VERSION "PDbcCodec 2.0.5"

NS_ :

BS_:

BU_: CanMatrix CanMatrixMZ1_Can CanMatrixMB1_Can CanMatrixMZ1_i40OSupplyActual CanMatrixMB1_i40OSupplyActual CanMatrixDigitemp_temp CanMatrixTUMG_IOLink

BO_ 385 Message_181: 7 CanMatrixMZ1_Can
 SG_ MZ1_Can_1_deg : 0|16@1+ (0.005493,0) [0|360] "°" Vector__XXX
 SG_ MZ1_Can_1_turn : 16|8@1+ (1,0) [0|3000] "turn" Vector__XXX

BO_ 386 Message_182: 7 CanMatrixMZ1_Can
 SG_ MZ1_Can_2_deg : 0|16@1+ (0.005493,0) [0|360] "°" Vector__XXX
 SG_ MZ1_Can_2_turn : 16|8@1+ (1,0) [0|3000] "turn" Vector__XXX

BO_ 387 Message_183: 7 CanMatrixMZ1_Can
 SG_ MZ1_Can_3_deg : 0|16@1+ (0.005493,0) [0|360] "°" Vector__XXX
 SG_ MZ1_Can_3_turn : 16|8@1+ (1,0) [0|3000] "turn" Vector__XXX

BO_ 388 Message_184: 7 CanMatrixMZ1_Can
 SG_ MZ1_Can_4_deg : 0|16@1+ (0.005493,0) [0|360] "°" Vector__XXX
 SG_ MZ1_Can_4_turn : 16|8@1+ (1,0) [0|3000] "turn" Vector__XXX

BO_ 389 Message_185: 7 CanMatrixMZ1_Can
 SG_ MZ1_Can_5_deg : 0|16@1+ (0.005493,0) [0|360] "°" Vector__XXX
 SG_ MZ1_Can_5_turn : 16|8@1+ (1,0) [0|3000] "turn" Vector__XXX

BO_ 390 Message_186: 7 CanMatrixMZ1_Can
 SG_ MZ1_Can_6_deg : 0|16@1+ (0.005493,0) [0|360] "°" Vector__XXX
 SG_ MZ1_Can_6_turn : 16|8@1+ (1,0) [0|3000] "turn" Vector__XXX

BO_ 391 Message_187: 7 CanMatrixMZ1_Can
 SG_ MZ1_Can_7_deg : 0|16@1+ (0.005493,0) [0|360] "°" Vector__XXX
 SG_ MZ1_Can_7_turn : 16|8@1+ (1,0) [0|3000] "turn" Vector__XXX

BO_ 392 Message_188: 7 CanMatrixMZ1_Can
 SG_ MZ1_Can_8_deg : 0|16@1+ (0.005493,0) [0|360] "°" Vector__XXX
 SG_ MZ1_Can_8_turn : 16|8@1+ (1,0) [0|3000] "turn" Vector__XXX

BO_ 393 Message_189: 7 CanMatrixMZ1_Can
 SG_ MZ1_Can_9_deg : 0|16@1+ (0.005493,0) [0|360] "°" Vector__XXX
 SG_ MZ1_Can_9_turn : 16|8@1+ (1,0) [0|3000] "turn" Vector__XXX

BO_ 394 Message_18A: 7 CanMatrixMZ1_Can
 SG_ MZ1_Can_10_deg : 0|16@1+ (0.005493,0) [0|360] "°" Vector__XXX
 SG_ MZ1_Can_10_turn : 16|8@1+ (1,0) [0|3000] "turn" Vector__XXX

BO_ 395 Message_18B: 7 CanMatrixMB1_Can
 SG_ MB1_Can_1_deg : 0|16@1+ (0.005493,0) [0|360] "°" Vector__XXX
 SG_ MB1_Can_1_turn : 16|8@1+ (1,0) [0|3000] "turn" Vector__XXX

BO_ 396 Message_18C: 7 CanMatrixMB1_Can
 SG_ MB1_Can_2_deg : 0|16@1+ (0.005493,0) [0|360] "°" Vector__XXX
 SG_ MB1_Can_2_turn : 16|8@1+ (1,0) [0|3000] "turn" Vector__XXX

BO_ 397 Message_18D: 7 CanMatrixMB1_Can
 SG_ MB1_Can_3_deg : 0|16@1+ (0.005493,0) [0|360] "°" Vector__XXX
 SG_ MB1_Can_3_turn : 16|8@1+ (1,0) [0|3000] "turn" Vector__XXX

BO_ 398 Message_18E: 7 CanMatrixMB1_Can
 SG_ MB1_Can_4_deg : 0|16@1+ (0.005493,0) [0|360] "°" Vector__XXX
 SG_ MB1_Can_4_turn : 16|8@1+ (1,0) [0|3000] "turn" Vector__XXX

BO_ 399 Message_18F: 7 CanMatrixMB1_Can
 SG_ MB1_Can_5_deg : 0|16@1+ (0.005493,0) [0|360] "°" Vector__XXX
 SG_ MB1_Can_5_turn : 16|8@1+ (1,0) [0|3000] "turn" Vector__XXX

BO_ 400 Message_190: 7 CanMatrixMB1_Can
 SG_ MB1_Can_6_deg : 0|16@1+ (0.005493,0) [0|360] "°" Vector__XXX
 SG_ MB1_Can_6_turn : 16|8@1+ (1,0) [0|3000] "turn" Vector__XXX

BO_ 401 Message_191: 7 CanMatrixMB1_Can
 SG_ MB1_Can_7_deg : 0|16@1+ (0.005493,0) [0|360] "°" Vector__XXX
 SG_ MB1_Can_7_turn : 16|8@1+ (1,0) [0|3000] "turn" Vector__XXX

BO_ 402 Message_192: 7 CanMatrixMB1_Can
 SG_ MB1_Can_8_deg : 0|16@1+ (0.005493,0) [0|360] "°" Vector__XXX
 SG_ MB1_Can_8_turn : 16|8@1+ (1,0) [0|3000] "turn" Vector__XXX

BO_ 403 Message_193: 7 CanMatrixMB1_Can
 SG_ MB1_Can_9_deg : 0|16@1+ (0.005493,0) [0|360] "°" Vector__XXX
 SG_ MB1_Can_9_turn : 16|8@1+ (1,0) [0|3000] "turn" Vector__XXX

BO_ 404 Message_194: 7 CanMatrixMB1_Can
 SG_ MB1_Can_10_deg : 0|16@1+ (0.005493,0) [0|360] "°" Vector__XXX
 SG_ MB1_Can_10_turn : 16|8@1+ (1,0) [0|3000] "turn" Vector__XXX

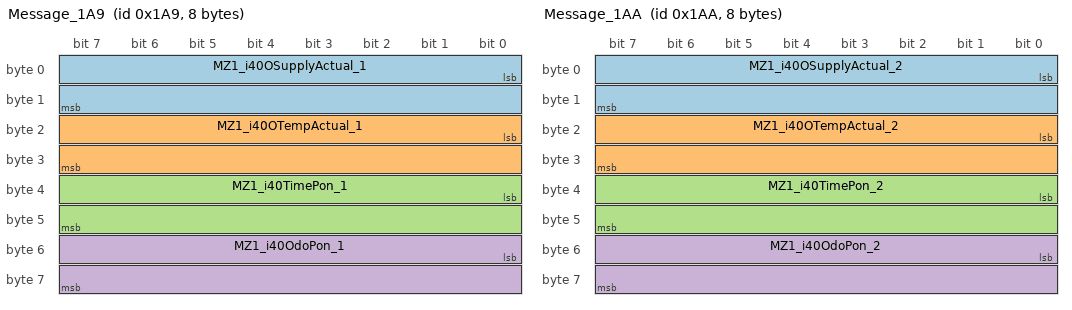
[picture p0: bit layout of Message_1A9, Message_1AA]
BO_ 425 Message_1A9: 8 CanMatrixMZ1_i40OSupplyActual
 SG_ MZ1_i40OSupplyActual_1 : 0|16@1+ (0.1,0) [0|3000] "V" Vector__XXX
 SG_ MZ1_i40OTempActual_1 : 16|16@1+ (0.1,-50) [0|3000] "°C" Vector__XXX
 SG_ MZ1_i40TimePon_1 : 32|16@1+ (1,0) [0|3000] "h" Vector__XXX
 SG_ MZ1_i40OdoPon_1 : 48|16@1+ (1,0) [0|3000] "h" Vector__XXX

BO_ 426 Message_1AA: 8 CanMatrixMZ1_i40OSupplyActual
 SG_ MZ1_i40OSupplyActual_2 : 0|16@1+ (0.1,0) [0|3000] "V" Vector__XXX
 SG_ MZ1_i40OTempActual_2 : 16|16@1+ (0.1,-50) [0|3000] "°C" Vector__XXX
 SG_ MZ1_i40TimePon_2 : 32|16@1+ (1,0) [0|3000] "h" Vector__XXX
 SG_ MZ1_i40OdoPon_2 : 48|16@1+ (1,0) [0|3000] "h" Vector__XXX

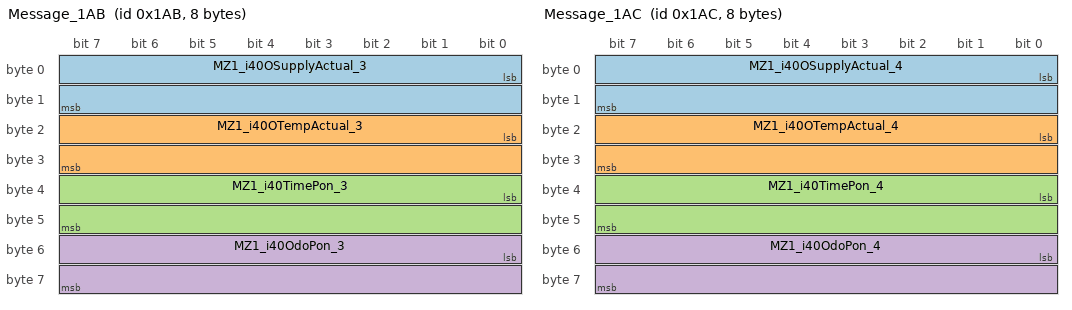
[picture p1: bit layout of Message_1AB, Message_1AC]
BO_ 427 Message_1AB: 8 CanMatrixMZ1_i40OSupplyActual
 SG_ MZ1_i40OSupplyActual_3 : 0|16@1+ (0.1,0) [0|3000] "V" Vector__XXX
 SG_ MZ1_i40OTempActual_3 : 16|16@1+ (0.1,-50) [0|3000] "°C" Vector__XXX
 SG_ MZ1_i40TimePon_3 : 32|16@1+ (1,0) [0|3000] "h" Vector__XXX
 SG_ MZ1_i40OdoPon_3 : 48|16@1+ (1,0) [0|3000] "h" Vector__XXX

BO_ 428 Message_1AC: 8 CanMatrixMZ1_i40OSupplyActual
 SG_ MZ1_i40OSupplyActual_4 : 0|16@1+ (0.1,0) [0|3000] "V" Vector__XXX
 SG_ MZ1_i40OTempActual_4 : 16|16@1+ (0.1,-50) [0|3000] "°C" Vector__XXX
 SG_ MZ1_i40TimePon_4 : 32|16@1+ (1,0) [0|3000] "h" Vector__XXX
 SG_ MZ1_i40OdoPon_4 : 48|16@1+ (1,0) [0|3000] "h" Vector__XXX

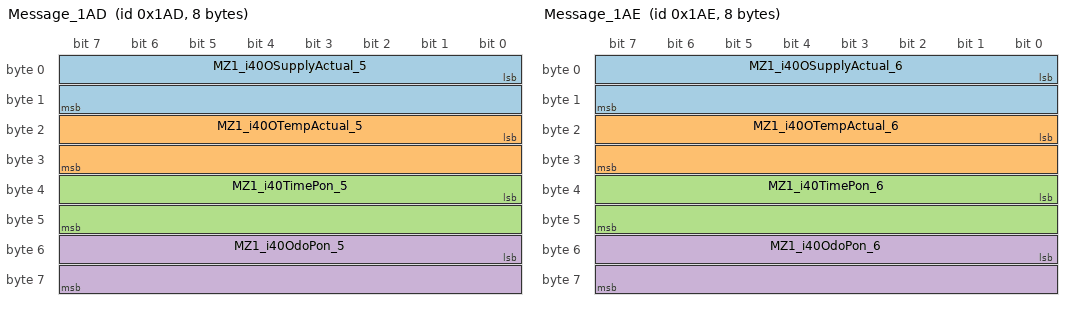
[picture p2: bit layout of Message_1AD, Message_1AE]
BO_ 429 Message_1AD: 8 CanMatrixMZ1_i40OSupplyActual
 SG_ MZ1_i40OSupplyActual_5 : 0|16@1+ (0.1,0) [0|3000] "V" Vector__XXX
 SG_ MZ1_i40OTempActual_5 : 16|16@1+ (0.1,-50) [0|3000] "°C" Vector__XXX
 SG_ MZ1_i40TimePon_5 : 32|16@1+ (1,0) [0|3000] "h" Vector__XXX
 SG_ MZ1_i40OdoPon_5 : 48|16@1+ (1,0) [0|3000] "h" Vector__XXX

BO_ 430 Message_1AE: 8 CanMatrixMZ1_i40OSupplyActual
 SG_ MZ1_i40OSupplyActual_6 : 0|16@1+ (0.1,0) [0|3000] "V" Vector__XXX
 SG_ MZ1_i40OTempActual_6 : 16|16@1+ (0.1,-50) [0|3000] "°C" Vector__XXX
 SG_ MZ1_i40TimePon_6 : 32|16@1+ (1,0) [0|3000] "h" Vector__XXX
 SG_ MZ1_i40OdoPon_6 : 48|16@1+ (1,0) [0|3000] "h" Vector__XXX

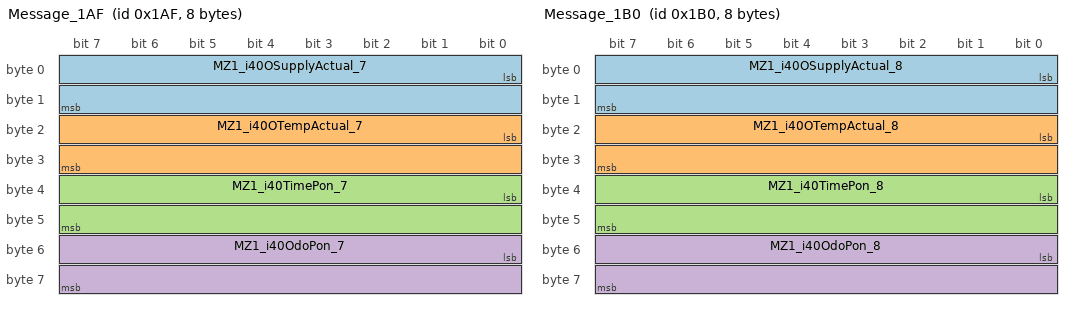
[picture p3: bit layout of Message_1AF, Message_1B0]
BO_ 431 Message_1AF: 8 CanMatrixMZ1_i40OSupplyActual
 SG_ MZ1_i40OSupplyActual_7 : 0|16@1+ (0.1,0) [0|3000] "V" Vector__XXX
 SG_ MZ1_i40OTempActual_7 : 16|16@1+ (0.1,-50) [0|3000] "°C" Vector__XXX
 SG_ MZ1_i40TimePon_7 : 32|16@1+ (1,0) [0|3000] "h" Vector__XXX
 SG_ MZ1_i40OdoPon_7 : 48|16@1+ (1,0) [0|3000] "h" Vector__XXX

BO_ 432 Message_1B0: 8 CanMatrixMZ1_i40OSupplyActual
 SG_ MZ1_i40OSupplyActual_8 : 0|16@1+ (0.1,0) [0|3000] "V" Vector__XXX
 SG_ MZ1_i40OTempActual_8 : 16|16@1+ (0.1,-50) [0|3000] "°C" Vector__XXX
 SG_ MZ1_i40TimePon_8 : 32|16@1+ (1,0) [0|3000] "h" Vector__XXX
 SG_ MZ1_i40OdoPon_8 : 48|16@1+ (1,0) [0|3000] "h" Vector__XXX

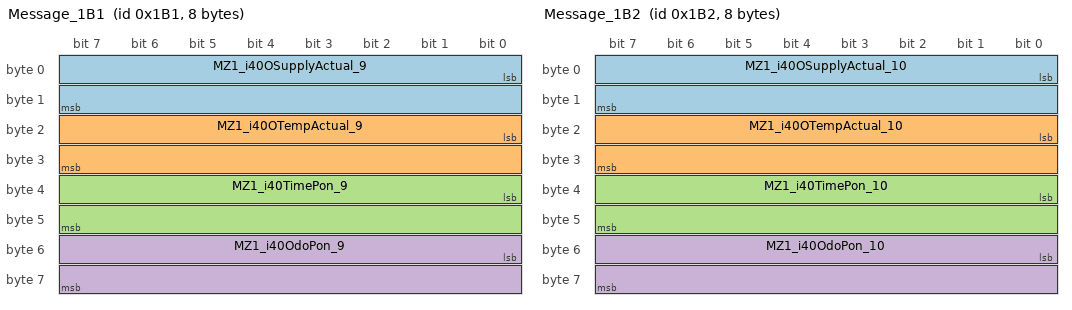
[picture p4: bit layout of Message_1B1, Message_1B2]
BO_ 433 Message_1B1: 8 CanMatrixMZ1_i40OSupplyActual
 SG_ MZ1_i40OSupplyActual_9 : 0|16@1+ (0.1,0) [0|3000] "V" Vector__XXX
 SG_ MZ1_i40OTempActual_9 : 16|16@1+ (0.1,-50) [0|3000] "°C" Vector__XXX
 SG_ MZ1_i40TimePon_9 : 32|16@1+ (1,0) [0|3000] "h" Vector__XXX
 SG_ MZ1_i40OdoPon_9 : 48|16@1+ (1,0) [0|3000] "h" Vector__XXX

BO_ 434 Message_1B2: 8 CanMatrixMZ1_i40OSupplyActual
 SG_ MZ1_i40OSupplyActual_10 : 0|16@1+ (0.1,0) [0|3000] "V" Vector__XXX
 SG_ MZ1_i40OTempActual_10 : 16|16@1+ (0.1,-50) [0|3000] "°C" Vector__XXX
 SG_ MZ1_i40TimePon_10 : 32|16@1+ (1,0) [0|3000] "h" Vector__XXX
 SG_ MZ1_i40OdoPon_10 : 48|16@1+ (1,0) [0|3000] "h" Vector__XXX

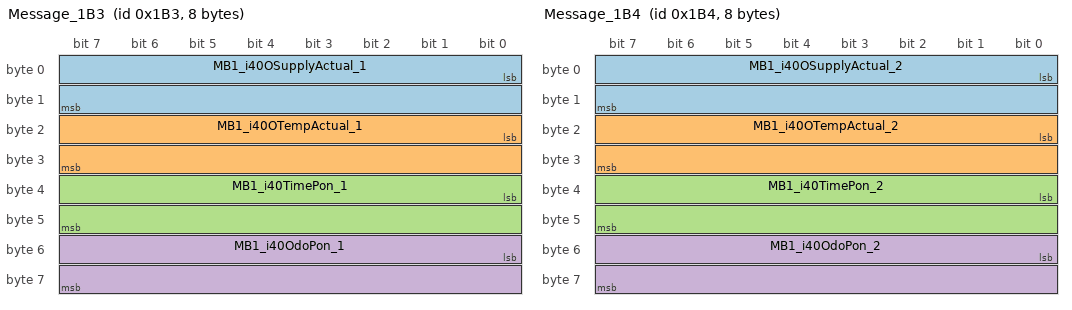
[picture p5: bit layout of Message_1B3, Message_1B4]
BO_ 435 Message_1B3: 8 CanMatrixMB1_i40OSupplyActual
 SG_ MB1_i40OSupplyActual_1 : 0|16@1+ (0.1,0) [0|3000] "V" Vector__XXX
 SG_ MB1_i40OTempActual_1 : 16|16@1+ (0.1,0) [0|3000] "°C" Vector__XXX
 SG_ MB1_i40TimePon_1 : 32|16@1+ (1,0) [0|3000] "h" Vector__XXX
 SG_ MB1_i40OdoPon_1 : 48|16@1+ (1,0) [0|3000] "h" Vector__XXX

BO_ 436 Message_1B4: 8 CanMatrixMB1_i40OSupplyActual
 SG_ MB1_i40OSupplyActual_2 : 0|16@1+ (0.1,0) [0|3000] "V" Vector__XXX
 SG_ MB1_i40OTempActual_2 : 16|16@1+ (0.1,0) [0|3000] "°C" Vector__XXX
 SG_ MB1_i40TimePon_2 : 32|16@1+ (1,0) [0|3000] "h" Vector__XXX
 SG_ MB1_i40OdoPon_2 : 48|16@1+ (1,0) [0|3000] "h" Vector__XXX

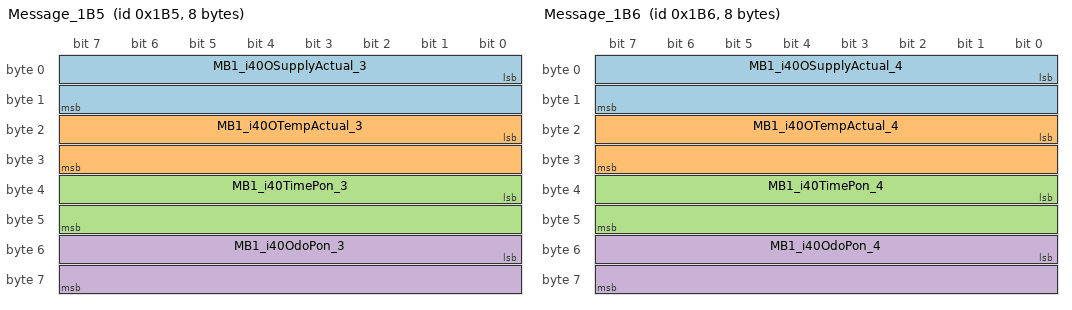
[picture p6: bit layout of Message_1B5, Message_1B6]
BO_ 437 Message_1B5: 8 CanMatrixMB1_i40OSupplyActual
 SG_ MB1_i40OSupplyActual_3 : 0|16@1+ (0.1,0) [0|3000] "V" Vector__XXX
 SG_ MB1_i40OTempActual_3 : 16|16@1+ (0.1,0) [0|3000] "°C" Vector__XXX
 SG_ MB1_i40TimePon_3 : 32|16@1+ (1,0) [0|3000] "h" Vector__XXX
 SG_ MB1_i40OdoPon_3 : 48|16@1+ (1,0) [0|3000] "h" Vector__XXX

BO_ 438 Message_1B6: 8 CanMatrixMB1_i40OSupplyActual
 SG_ MB1_i40OSupplyActual_4 : 0|16@1+ (0.1,0) [0|3000] "V" Vector__XXX
 SG_ MB1_i40OTempActual_4 : 16|16@1+ (0.1,0) [0|3000] "°C" Vector__XXX
 SG_ MB1_i40TimePon_4 : 32|16@1+ (1,0) [0|3000] "h" Vector__XXX
 SG_ MB1_i40OdoPon_4 : 48|16@1+ (1,0) [0|3000] "h" Vector__XXX

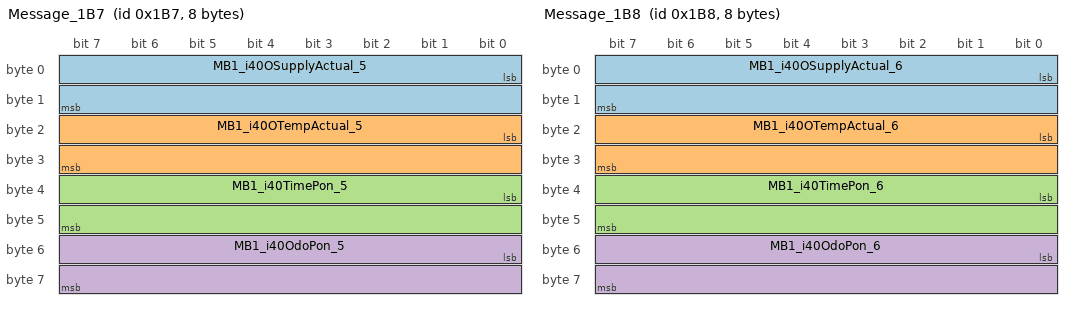
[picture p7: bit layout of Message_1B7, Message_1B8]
BO_ 439 Message_1B7: 8 CanMatrixMB1_i40OSupplyActual
 SG_ MB1_i40OSupplyActual_5 : 0|16@1+ (0.1,0) [0|3000] "V" Vector__XXX
 SG_ MB1_i40OTempActual_5 : 16|16@1+ (0.1,0) [0|3000] "°C" Vector__XXX
 SG_ MB1_i40TimePon_5 : 32|16@1+ (1,0) [0|3000] "h" Vector__XXX
 SG_ MB1_i40OdoPon_5 : 48|16@1+ (1,0) [0|3000] "h" Vector__XXX

BO_ 440 Message_1B8: 8 CanMatrixMB1_i40OSupplyActual
 SG_ MB1_i40OSupplyActual_6 : 0|16@1+ (0.1,0) [0|3000] "V" Vector__XXX
 SG_ MB1_i40OTempActual_6 : 16|16@1+ (0.1,0) [0|3000] "°C" Vector__XXX
 SG_ MB1_i40TimePon_6 : 32|16@1+ (1,0) [0|3000] "h" Vector__XXX
 SG_ MB1_i40OdoPon_6 : 48|16@1+ (1,0) [0|3000] "h" Vector__XXX

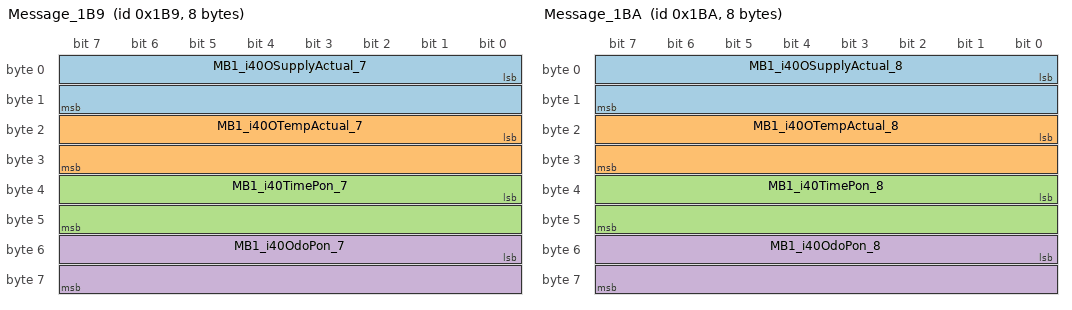
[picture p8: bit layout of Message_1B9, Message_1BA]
BO_ 441 Message_1B9: 8 CanMatrixMB1_i40OSupplyActual
 SG_ MB1_i40OSupplyActual_7 : 0|16@1+ (0.1,0) [0|3000] "V" Vector__XXX
 SG_ MB1_i40OTempActual_7 : 16|16@1+ (0.1,0) [0|3000] "°C" Vector__XXX
 SG_ MB1_i40TimePon_7 : 32|16@1+ (1,0) [0|3000] "h" Vector__XXX
 SG_ MB1_i40OdoPon_7 : 48|16@1+ (1,0) [0|3000] "h" Vector__XXX

BO_ 442 Message_1BA: 8 CanMatrixMB1_i40OSupplyActual
 SG_ MB1_i40OSupplyActual_8 : 0|16@1+ (0.1,0) [0|3000] "V" Vector__XXX
 SG_ MB1_i40OTempActual_8 : 16|16@1+ (0.1,0) [0|3000] "°C" Vector__XXX
 SG_ MB1_i40TimePon_8 : 32|16@1+ (1,0) [0|3000] "h" Vector__XXX
 SG_ MB1_i40OdoPon_8 : 48|16@1+ (1,0) [0|3000] "h" Vector__XXX

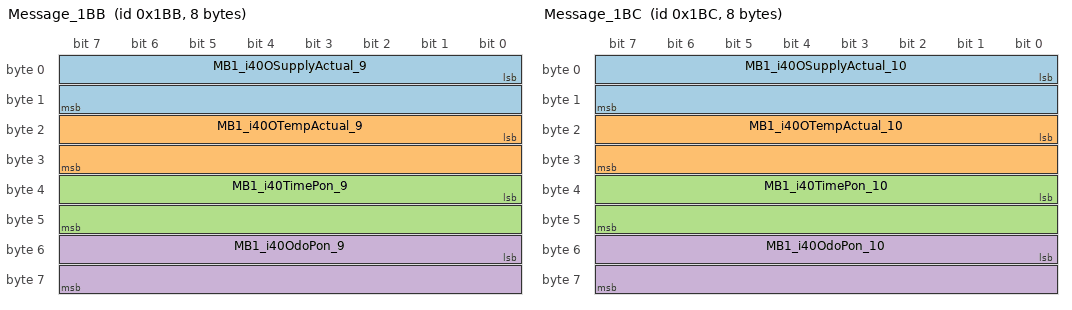
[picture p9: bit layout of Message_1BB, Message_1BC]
BO_ 443 Message_1BB: 8 CanMatrixMB1_i40OSupplyActual
 SG_ MB1_i40OSupplyActual_9 : 0|16@1+ (0.1,0) [0|3000] "V" Vector__XXX
 SG_ MB1_i40OTempActual_9 : 16|16@1+ (0.1,0) [0|3000] "°C" Vector__XXX
 SG_ MB1_i40TimePon_9 : 32|16@1+ (1,0) [0|3000] "h" Vector__XXX
 SG_ MB1_i40OdoPon_9 : 48|16@1+ (1,0) [0|3000] "h" Vector__XXX

BO_ 444 Message_1BC: 8 CanMatrixMB1_i40OSupplyActual
 SG_ MB1_i40OSupplyActual_10 : 0|16@1+ (0.1,0) [0|3000] "V" Vector__XXX
 SG_ MB1_i40OTempActual_10 : 16|16@1+ (0.1,0) [0|3000] "°C" Vector__XXX
 SG_ MB1_i40TimePon_10 : 32|16@1+ (1,0) [0|3000] "h" Vector__XXX
 SG_ MB1_i40OdoPon_10 : 48|16@1+ (1,0) [0|3000] "h" Vector__XXX

BO_ 900 Message_384: 4 CanMatrixDigitemp_temp
 SG_ Digitemp_temp_HYT : 0|16@1+ (0.01,-40) [-40|125] "°C" Vector__XXX
 SG_ Digitemp_RF_HYT : 16|16@1+ (0.01,0) [0|0] "%" Vector__XXX

BO_ 800 Message_320: 2 CanMatrixTUMG_IOLink
 SG_ TUMG_IOLink : 0|16@1+ (0.007081,-48.5) [0|200] "°C" Vector__XXX

CM_ SG_ 385 MZ1_Can_1_deg " Winkelwert MZ1_Can_1_deg P01059 Winkelwert MZ1_Can_1_deg P01059";
CM_ SG_ 385 MZ1_Can_1_turn " Umdrehung MZ1_Can_1_turn P01059";
CM_ SG_ 386 MZ1_Can_2_deg " Winkelwert MZ1_Can_2_deg P01059 Winkelwert MZ1_Can_2_deg P01059";
CM_ SG_ 386 MZ1_Can_2_turn " Umdrehung MZ1_Can_2_turn P01059";
CM_ SG_ 387 MZ1_Can_3_deg " Winkelwert MZ1_Can_3_deg P01059 Winkelwert MZ1_Can_3_deg P01059";
CM_ SG_ 387 MZ1_Can_3_turn " Umdrehung MZ1_Can_3_turn P01059";
CM_ SG_ 388 MZ1_Can_4_deg " Winkelwert MZ1_Can_4_deg P01059 Winkelwert MZ1_Can_4_deg P01059";
CM_ SG_ 388 MZ1_Can_4_turn " Umdrehung MZ1_Can_4_turn P01059";
CM_ SG_ 389 MZ1_Can_5_deg " Winkelwert MZ1_Can_5_deg P01059 Winkelwert MZ1_Can_5_deg P01059";
CM_ SG_ 389 MZ1_Can_5_turn " Umdrehung MZ1_Can_5_turn P01059";
CM_ SG_ 390 MZ1_Can_6_deg " Winkelwert MZ1_Can_6_deg P01059 Winkelwert MZ1_Can_6_deg P01059";
CM_ SG_ 390 MZ1_Can_6_turn " Umdrehung MZ1_Can_6_turn P01059";
CM_ SG_ 391 MZ1_Can_7_deg " Winkelwert MZ1_Can_7_deg P01059 Winkelwert MZ1_Can_7_deg P01059";
CM_ SG_ 391 MZ1_Can_7_turn " Umdrehung MZ1_Can_7_turn P01059";
CM_ SG_ 392 MZ1_Can_8_deg " Winkelwert MZ1_Can_8_deg P01059 Winkelwert MZ1_Can_8_deg P01059";
CM_ SG_ 392 MZ1_Can_8_turn " Umdrehung MZ1_Can_8_turn P01059";
CM_ SG_ 393 MZ1_Can_9_deg " Winkelwert MZ1_Can_9_deg P01059 Winkelwert MZ1_Can_9_deg P01059";
CM_ SG_ 393 MZ1_Can_9_turn " Umdrehung MZ1_Can_9_turn P01059";
CM_ SG_ 394 MZ1_Can_10_deg " Winkelwert MZ1_Can_10_deg P01059 Winkelwert MZ1_Can_10_deg P01059";
CM_ SG_ 394 MZ1_Can_10_turn " Umdrehung MZ1_Can_10_turn P01059";
CM_ SG_ 395 MB1_Can_1_deg " Winkelwert MB1_Can_1_deg P01059 Winkelwert MB1_Can_1_deg P01059";
CM_ SG_ 395 MB1_Can_1_turn " Umdrehung MB1_Can_1_turn P01059";
CM_ SG_ 396 MB1_Can_2_deg " Winkelwert MB1_Can_2_deg P01059 Winkelwert MB1_Can_2_deg P01059";
CM_ SG_ 396 MB1_Can_2_turn " Umdrehung MB1_Can_2_turn P01059";
CM_ SG_ 397 MB1_Can_3_deg " Winkelwert MB1_Can_3_deg P01059 Winkelwert MB1_Can_3_deg P01059";
CM_ SG_ 397 MB1_Can_3_turn " Umdrehung MB1_Can_3_turn P01059";
CM_ SG_ 398 MB1_Can_4_deg " Winkelwert MB1_Can_4_deg P01059 Winkelwert MB1_Can_4_deg P01059";
CM_ SG_ 398 MB1_Can_4_turn " Umdrehung MB1_Can_4_turn P01059";
CM_ SG_ 399 MB1_Can_5_deg " Winkelwert MB1_Can_5_deg P01059 Winkelwert MB1_Can_5_deg P01059";
CM_ SG_ 399 MB1_Can_5_turn " Umdrehung MB1_Can_5_turn P01059";
CM_ SG_ 400 MB1_Can_6_deg " Winkelwert MB1_Can_6_deg P01059 Winkelwert MB1_Can_6_deg P01059";
CM_ SG_ 400 MB1_Can_6_turn " Umdrehung MB1_Can_6_turn P01059";
CM_ SG_ 401 MB1_Can_7_deg " Winkelwert MB1_Can_7_deg P01059 Winkelwert MB1_Can_7_deg P01059";
CM_ SG_ 401 MB1_Can_7_turn " Umdrehung MB1_Can_7_turn P01059";
CM_ SG_ 402 MB1_Can_8_deg " Winkelwert MB1_Can_8_deg P01059 Winkelwert MB1_Can_8_deg P01059";
CM_ SG_ 402 MB1_Can_8_turn " Umdrehung MB1_Can_8_turn P01059";
CM_ SG_ 403 MB1_Can_9_deg " Winkelwert MB1_Can_9_deg P01059 Winkelwert MB1_Can_9_deg P01059";
CM_ SG_ 403 MB1_Can_9_turn " Umdrehung MB1_Can_9_turn P01059";
CM_ SG_ 404 MB1_Can_10_deg " Winkelwert MB1_Can_10_deg P01059 Winkelwert MB1_Can_10_deg P01059";
CM_ SG_ 404 MB1_Can_10_turn " Umdrehung MB1_Can_10_turn P01059";
CM_ SG_ 425 MZ1_i40OSupplyActual_1 " SDO MZ1_i40OSupplyActual_1 SDO MZ1_i40OSupplyActual_1";
CM_ SG_ 425 MZ1_i40OTempActual_1 " SDO MZ1_i40OTempActual_1";
CM_ SG_ 425 MZ1_i40TimePon_1 " SDO MZ1_i40TimePon_1";
CM_ SG_ 425 MZ1_i40OdoPon_1 " SDO MZ1_i40OdoPon_1";
CM_ SG_ 426 MZ1_i40OSupplyActual_2 " SDO MZ1_i40OSupplyActual_2 SDO MZ1_i40OSupplyActual_2";
CM_ SG_ 426 MZ1_i40OTempActual_2 " SDO MZ1_i40OTempActual_2";
CM_ SG_ 426 MZ1_i40TimePon_2 " SDO MZ1_i40TimePon_2";
CM_ SG_ 426 MZ1_i40OdoPon_2 " SDO MZ1_i40OdoPon_2";
CM_ SG_ 427 MZ1_i40OSupplyActual_3 " SDO MZ1_i40OSupplyActual_3 SDO MZ1_i40OSupplyActual_3";
CM_ SG_ 427 MZ1_i40OTempActual_3 " SDO MZ1_i40OTempActual_3";
CM_ SG_ 427 MZ1_i40TimePon_3 " SDO MZ1_i40TimePon_3";
CM_ SG_ 427 MZ1_i40OdoPon_3 " SDO MZ1_i40OdoPon_3";
CM_ SG_ 428 MZ1_i40OSupplyActual_4 " SDO MZ1_i40OSupplyActual_4 SDO MZ1_i40OSupplyActual_4";
CM_ SG_ 428 MZ1_i40OTempActual_4 " SDO MZ1_i40OTempActual_4";
CM_ SG_ 428 MZ1_i40TimePon_4 " SDO MZ1_i40TimePon_4";
CM_ SG_ 428 MZ1_i40OdoPon_4 " SDO MZ1_i40OdoPon_4";
CM_ SG_ 429 MZ1_i40OSupplyActual_5 " SDO MZ1_i40OSupplyActual_5 SDO MZ1_i40OSupplyActual_5";
CM_ SG_ 429 MZ1_i40OTempActual_5 " SDO MZ1_i40OTempActual_5";
CM_ SG_ 429 MZ1_i40TimePon_5 " SDO MZ1_i40TimePon_5";
CM_ SG_ 429 MZ1_i40OdoPon_5 " SDO MZ1_i40OdoPon_5";
CM_ SG_ 430 MZ1_i40OSupplyActual_6 " SDO MZ1_i40OSupplyActual_6 SDO MZ1_i40OSupplyActual_6";
CM_ SG_ 430 MZ1_i40OTempActual_6 " SDO MZ1_i40OTempActual_6";
CM_ SG_ 430 MZ1_i40TimePon_6 " SDO MZ1_i40TimePon_6";
CM_ SG_ 430 MZ1_i40OdoPon_6 " SDO MZ1_i40OdoPon_6";
CM_ SG_ 431 MZ1_i40OSupplyActual_7 " SDO MZ1_i40OSupplyActual_7 SDO MZ1_i40OSupplyActual_7";
CM_ SG_ 431 MZ1_i40OTempActual_7 " SDO MZ1_i40OTempActual_7";
CM_ SG_ 431 MZ1_i40TimePon_7 " SDO MZ1_i40TimePon_7";
CM_ SG_ 431 MZ1_i40OdoPon_7 " SDO MZ1_i40OdoPon_7";
CM_ SG_ 432 MZ1_i40OSupplyActual_8 " SDO MZ1_i40OSupplyActual_8 SDO MZ1_i40OSupplyActual_8";
CM_ SG_ 432 MZ1_i40OTempActual_8 " SDO MZ1_i40OTempActual_8";
CM_ SG_ 432 MZ1_i40TimePon_8 " SDO MZ1_i40TimePon_8";
CM_ SG_ 432 MZ1_i40OdoPon_8 " SDO MZ1_i40OdoPon_8";
CM_ SG_ 433 MZ1_i40OSupplyActual_9 " SDO MZ1_i40OSupplyActual_9 SDO MZ1_i40OSupplyActual_9";
CM_ SG_ 433 MZ1_i40OTempActual_9 " SDO MZ1_i40OTempActual_9";
CM_ SG_ 433 MZ1_i40TimePon_9 " SDO MZ1_i40TimePon_9";
CM_ SG_ 433 MZ1_i40OdoPon_9 " SDO MZ1_i40OdoPon_9";
CM_ SG_ 434 MZ1_i40OSupplyActual_10 " SDO MZ1_i40OSupplyActual_10 SDO MZ1_i40OSupplyActual_10";
CM_ SG_ 434 MZ1_i40OTempActual_10 " SDO MZ1_i40OTempActual_10";
CM_ SG_ 434 MZ1_i40TimePon_10 " SDO MZ1_i40TimePon_10";
CM_ SG_ 434 MZ1_i40OdoPon_10 " SDO MZ1_i40OdoPon_10";
CM_ SG_ 435 MB1_i40OSupplyActual_1 " SDO MB1_i40OSupplyActual_1 SDO MB1_i40OSupplyActual_1";
CM_ SG_ 435 MB1_i40OTempActual_1 " SDO MB1_i40OTempActual_1";
CM_ SG_ 435 MB1_i40TimePon_1 " SDO MB1_i40TimePon_1";
CM_ SG_ 435 MB1_i40OdoPon_1 " SDO MB1_i40OdoPon_1";
CM_ SG_ 436 MB1_i40OSupplyActual_2 " SDO MB1_i40OSupplyActual_2 SDO MB1_i40OSupplyActual_2";
CM_ SG_ 436 MB1_i40OTempActual_2 " SDO MB1_i40OTempActual_2";
CM_ SG_ 436 MB1_i40TimePon_2 " SDO MB1_i40TimePon_2";
CM_ SG_ 436 MB1_i40OdoPon_2 " SDO MB1_i40OdoPon_2";
CM_ SG_ 437 MB1_i40OSupplyActual_3 " SDO MB1_i40OSupplyActual_3 SDO MB1_i40OSupplyActual_3";
CM_ SG_ 437 MB1_i40OTempActual_3 " SDO MB1_i40OTempActual_3";
CM_ SG_ 437 MB1_i40TimePon_3 " SDO MB1_i40TimePon_3";
CM_ SG_ 437 MB1_i40OdoPon_3 " SDO MB1_i40OdoPon_3";
CM_ SG_ 438 MB1_i40OSupplyActual_4 " SDO MB1_i40OSupplyActual_4 SDO MB1_i40OSupplyActual_4";
CM_ SG_ 438 MB1_i40OTempActual_4 " SDO MB1_i40OTempActual_4";
CM_ SG_ 438 MB1_i40TimePon_4 " SDO MB1_i40TimePon_4";
CM_ SG_ 438 MB1_i40OdoPon_4 " SDO MB1_i40OdoPon_4";
CM_ SG_ 439 MB1_i40OSupplyActual_5 " SDO MB1_i40OSupplyActual_5 SDO MB1_i40OSupplyActual_5";
CM_ SG_ 439 MB1_i40OTempActual_5 " SDO MB1_i40OTempActual_5";
CM_ SG_ 439 MB1_i40TimePon_5 " SDO MB1_i40TimePon_5";
CM_ SG_ 439 MB1_i40OdoPon_5 " SDO MB1_i40OdoPon_5";
CM_ SG_ 440 MB1_i40OSupplyActual_6 " SDO MB1_i40OSupplyActual_6 SDO MB1_i40OSupplyActual_6";
CM_ SG_ 440 MB1_i40OTempActual_6 " SDO MB1_i40OTempActual_6";
CM_ SG_ 440 MB1_i40TimePon_6 " SDO MB1_i40TimePon_6";
CM_ SG_ 440 MB1_i40OdoPon_6 " SDO MB1_i40OdoPon_6";
CM_ SG_ 441 MB1_i40OSupplyActual_7 " SDO MB1_i40OSupplyActual_7 SDO MB1_i40OSupplyActual_7";
CM_ SG_ 441 MB1_i40OTempActual_7 " SDO MB1_i40OTempActual_7";
CM_ SG_ 441 MB1_i40TimePon_7 " SDO MB1_i40TimePon_7";
CM_ SG_ 441 MB1_i40OdoPon_7 " SDO MB1_i40OdoPon_7";
CM_ SG_ 442 MB1_i40OSupplyActual_8 " SDO MB1_i40OSupplyActual_8 SDO MB1_i40OSupplyActual_8";
CM_ SG_ 442 MB1_i40OTempActual_8 " SDO MB1_i40OTempActual_8";
CM_ SG_ 442 MB1_i40TimePon_8 " SDO MB1_i40TimePon_8";
CM_ SG_ 442 MB1_i40OdoPon_8 " SDO MB1_i40OdoPon_8";
CM_ SG_ 443 MB1_i40OSupplyActual_9 " SDO MB1_i40OSupplyActual_9 SDO MB1_i40OSupplyActual_9";
CM_ SG_ 443 MB1_i40OTempActual_9 " SDO MB1_i40OTempActual_9";
CM_ SG_ 443 MB1_i40TimePon_9 " SDO MB1_i40TimePon_9";
CM_ SG_ 443 MB1_i40OdoPon_9 " SDO MB1_i40OdoPon_9";
CM_ SG_ 444 MB1_i40OSupplyActual_10 " SDO MB1_i40OSupplyActual_10 SDO MB1_i40OSupplyActual_10";
CM_ SG_ 444 MB1_i40OTempActual_10 " SDO MB1_i40OTempActual_10";
CM_ SG_ 444 MB1_i40TimePon_10 " SDO MB1_i40TimePon_10";
CM_ SG_ 444 MB1_i40OdoPon_10 " SDO MB1_i40OdoPon_10";
CM_ SG_ 900 Digitemp_temp_HYT " SDO Digitemp_temp_HYT SDO Digitemp_temp_HYT";
CM_ SG_ 900 Digitemp_RF_HYT " SDO Digitemp_RF_HYT";
CM_ SG_ 800 TUMG_IOLink " SDO TUMG_IOLink SDO TUMG_IOLink";
BA_DEF_ BO_  "GenMsgCycleTime" INT 0 100000;
BA_DEF_ BO_  "GenMsgSendType" ENUM  "cyclicX","spontanX","cyclicIfActiveX","spontanWithDelay","cyclicAndSpontanX","cyclicAndSpontanWithDelay","spontanWithRepitition","cyclicIfActiveAndSpontanWD","NoMsgSendType","cyclicWithRepeatOnDemand";
BA_DEF_  "Baudrate" INT 0 1000000;
BA_DEF_DEF_  "GenMsgCycleTime" 0;
BA_DEF_DEF_  "GenMsgSendType" "";
BA_DEF_DEF_  "Baudrate" 500000;
BA_ "GenMsgCycleTime" BO_ 385 1000;
BA_ "GenMsgSendType" BO_ 385 0;
BA_ "GenMsgCycleTime" BO_ 386 1000;
BA_ "GenMsgSendType" BO_ 386 0;
BA_ "GenMsgCycleTime" BO_ 387 1000;
BA_ "GenMsgSendType" BO_ 387 0;
BA_ "GenMsgCycleTime" BO_ 388 1000;
BA_ "GenMsgSendType" BO_ 388 0;
BA_ "GenMsgCycleTime" BO_ 389 1000;
BA_ "GenMsgSendType" BO_ 389 0;
BA_ "GenMsgCycleTime" BO_ 390 1000;
BA_ "GenMsgSendType" BO_ 390 0;
BA_ "GenMsgCycleTime" BO_ 391 1000;
BA_ "GenMsgSendType" BO_ 391 0;
BA_ "GenMsgCycleTime" BO_ 392 1000;
BA_ "GenMsgSendType" BO_ 392 0;
BA_ "GenMsgCycleTime" BO_ 393 1000;
BA_ "GenMsgSendType" BO_ 393 0;
BA_ "GenMsgCycleTime" BO_ 394 1000;
BA_ "GenMsgSendType" BO_ 394 0;
BA_ "GenMsgCycleTime" BO_ 395 1000;
BA_ "GenMsgSendType" BO_ 395 0;
BA_ "GenMsgCycleTime" BO_ 396 1000;
BA_ "GenMsgSendType" BO_ 396 0;
BA_ "GenMsgCycleTime" BO_ 397 1000;
BA_ "GenMsgSendType" BO_ 397 0;
BA_ "GenMsgCycleTime" BO_ 398 1000;
BA_ "GenMsgSendType" BO_ 398 0;
BA_ "GenMsgCycleTime" BO_ 399 1000;
BA_ "GenMsgSendType" BO_ 399 0;
BA_ "GenMsgCycleTime" BO_ 400 1000;
BA_ "GenMsgSendType" BO_ 400 0;
BA_ "GenMsgCycleTime" BO_ 401 1000;
BA_ "GenMsgSendType" BO_ 401 0;
BA_ "GenMsgCycleTime" BO_ 402 1000;
BA_ "GenMsgSendType" BO_ 402 0;
BA_ "GenMsgCycleTime" BO_ 403 1000;
BA_ "GenMsgSendType" BO_ 403 0;
BA_ "GenMsgCycleTime" BO_ 404 1000;
BA_ "GenMsgSendType" BO_ 404 0;
BA_ "GenMsgCycleTime" BO_ 425 1000;
BA_ "GenMsgSendType" BO_ 425 0;
BA_ "GenMsgCycleTime" BO_ 426 1000;
BA_ "GenMsgSendType" BO_ 426 0;
BA_ "GenMsgCycleTime" BO_ 427 1000;
BA_ "GenMsgSendType" BO_ 427 0;
BA_ "GenMsgCycleTime" BO_ 428 1000;
BA_ "GenMsgSendType" BO_ 428 0;
BA_ "GenMsgCycleTime" BO_ 429 1000;
BA_ "GenMsgSendType" BO_ 429 0;
BA_ "GenMsgCycleTime" BO_ 430 1000;
BA_ "GenMsgSendType" BO_ 430 0;
BA_ "GenMsgCycleTime" BO_ 431 1000;
BA_ "GenMsgSendType" BO_ 431 0;
BA_ "GenMsgCycleTime" BO_ 432 1000;
BA_ "GenMsgSendType" BO_ 432 0;
BA_ "GenMsgCycleTime" BO_ 433 1000;
BA_ "GenMsgSendType" BO_ 433 0;
BA_ "GenMsgCycleTime" BO_ 434 1000;
BA_ "GenMsgSendType" BO_ 434 0;
BA_ "GenMsgCycleTime" BO_ 435 1000;
BA_ "GenMsgSendType" BO_ 435 0;
BA_ "GenMsgCycleTime" BO_ 436 1000;
BA_ "GenMsgSendType" BO_ 436 0;
BA_ "GenMsgCycleTime" BO_ 437 1000;
BA_ "GenMsgSendType" BO_ 437 0;
BA_ "GenMsgCycleTime" BO_ 438 1000;
BA_ "GenMsgSendType" BO_ 438 0;
BA_ "GenMsgCycleTime" BO_ 439 1000;
BA_ "GenMsgSendType" BO_ 439 0;
BA_ "GenMsgCycleTime" BO_ 440 1000;
BA_ "GenMsgSendType" BO_ 440 0;
BA_ "GenMsgCycleTime" BO_ 441 1000;
BA_ "GenMsgSendType" BO_ 441 0;
BA_ "GenMsgCycleTime" BO_ 442 1000;
BA_ "GenMsgSendType" BO_ 442 0;
BA_ "GenMsgCycleTime" BO_ 443 1000;
BA_ "GenMsgSendType" BO_ 443 0;
BA_ "GenMsgCycleTime" BO_ 444 1000;
BA_ "GenMsgSendType" BO_ 444 0;
BA_ "GenMsgCycleTime" BO_ 900 1000;
BA_ "GenMsgSendType" BO_ 900 0;
BA_ "GenMsgCycleTime" BO_ 800 1000;
BA_ "GenMsgSendType" BO_ 800 0;
